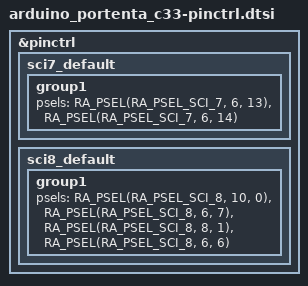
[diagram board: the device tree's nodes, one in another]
/*
 * Copyright (c) 2024 Ian Morris
 *
 * SPDX-License-Identifier: Apache-2.0
 */

&pinctrl {
	sci7_default: sci7_default {
		group1 {
			/* tx rx */
			psels = <RA_PSEL(RA_PSEL_SCI_7, 6, 13)>,
			<RA_PSEL(RA_PSEL_SCI_7, 6, 14)>;
		};
	};
	sci8_default: sci8_default {
		group1 {
			/* txd rxd, cts, rts */
			psels = <RA_PSEL(RA_PSEL_SCI_8, 10, 0)>,
			<RA_PSEL(RA_PSEL_SCI_8, 6, 7)>,
			<RA_PSEL(RA_PSEL_SCI_8, 8, 1)>,
			<RA_PSEL(RA_PSEL_SCI_8, 6, 6)>;
		};
	};
};
